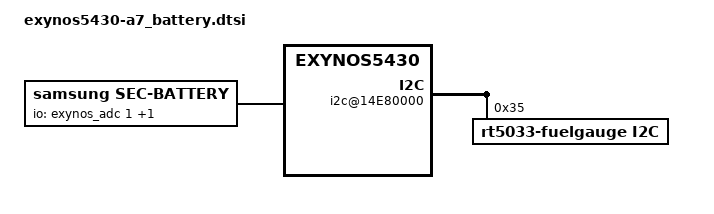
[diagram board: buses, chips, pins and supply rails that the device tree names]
/*
 * SAMSUNG UNIVERSAL5430 board device tree source
 *
 * Copyright (c) 2013 Samsung Electronics Co., Ltd.
 *		http://www.samsung.com
 *
 * This program is free software; you can redistribute it and/or modify
 * it under the terms of the GNU General Public License version 2 as
 * published by the Free Software Foundation.
*/

/ {
	i2c@14E80000 {
		compatible = "samsung,s3c2440-i2c";
		reg = <0x14E80000 0x1000>;
		interrupts = <0 443 0>;
		#address-cells = <1>;
		#size-cells = <0>;
		pinctrl-names = "default";
		pinctrl-0 = <&i2c4_bus>;
		clocks = <&clock 897>, <&clock 2447>;
		clock-names = "rate_i2c","gate_i2c";
		status = "okay";
		
		rt5033-fuelgauge@35 {
			compatible = "rt5033-fuelgauge,i2c";
			reg = <0x35>;
			interrupt-parent = <&gpa1>;
			pinctrl-names = "default";
			pinctrl-0 = <&fuel_irq>;
			
			fuelgauge,irqf = "IRQF_TRIGGER_FALLING + IRQF_ONESHOT + IRQF_NO_SUSPEND";
			fuelgauge,fuel_int = <&gpa1 5 0>;
			fuelgauge,capacity_max = <1000>;
			fuelgauge,capacity_max_margin = <50>;
			fuelgauge,capacity_min = <0>;
			fuelgauge,capacity_calculation_type = <0x17>;
			fuelgauge,fuel_alert_soc = <1>;
		};
	};

	battery {
		status = "okay";
		compatible = "samsung,sec-battery";
		battery,vendor = "SDI SDI";
		battery,charger_name = "rt5033-charger";
		battery,fuelgauge_name = "rt5033-fuelgauge";
		battery,technology = <2>; /* POWER_SUPPLY_TECHNOLOGY_LION */

		battery,chip_vendor = "LSI";
		battery,temp_adc_type = <1>; /* SEC_BATTERY_ADC_TYPE_AP */

		battery,polling_time = <10 30 30 30 3600>;

		battery,chg_temp_check = <0>;
		
		battery,inbat_voltage = <1>;




		battery,inbat_voltage_table_adc = <2902 2874 2850 2864 2796 2793 2785 2789 2781 2763
							2757 2745 2734 2724 2710 2700 2689 2679 2669 2654
							2638 2621 2612 2611 2591 2586 2574 2572 2548 2538
							2529 2510 2498 2484 2481 2468 2457 2448 2436 2421
							2404 2397 2382 2373 2357 2346 2337 2322 2308 2296
							2285 2271 2259 2250 2233>;

		battery,inbat_voltage_table_data = <4345 4325 4301 4282 4217 4215 4208 4206 4193 4173
							4153 4136 4117 4098 4078 4058 4041 4018 4001 3982
							3963 3945 3927 3908 3887 3868 3850 3832 3813 3792
							3775 3756 3737 3718 3698 3680 3661 3642 3623 3603
							3585 3563 3546 3528 3507 3488 3467 3443 3430 3400
							3383 3366 3346 3325 3301>;


		battery,temp_table_adc = <265 325 401 485 570 658 762 890 1036 1203
					1385 1591 1810 2035 2274 2507 2725 2938 3055 3120
					3190 3230 3300 3355 3480 3610 3700>;
		battery,temp_table_data = <900 850 800 750 700 650 600 550 500 450
					400 350 300 250 200 150 100 50 20 0
					(-20) (-30) (-50) (-70) (-100) (-150) (-200)>;
		battery,adc_check_count = <5>;

		battery,input_current_limit = <1500 500 500 1500 500 1000 1000 500 500 1000 1000 1500 1500 500 1000 500 700 1000 500 1000 1500 500 500>;
		battery,fast_charging_current = <2000 0 500 2000 500 1000 1000 500 0 1200 2000 2000 2000 (-1) 1300 500 800 1300 500 1000 2000 0 0>;
		battery,full_check_current_1st = <200 0 200 200 200 200 200 200 0 200 200 200 200 0 200 200 200 200 200 200 200 0 0>;
		battery,full_check_current_2nd = <2400 0 2400 2400 2400 2400 2400 2400 0 2400 2400 2400 2400 0 2400 2400 2400 2400 2400 2400 2400 0 0>;


	
	
		battery,cable_check_type = <4>; /* SEC_BATTERY_CABLE_CHECK_PSY */
		battery,cable_source_type = <3>; /* SEC_BATTERY_CABLE_SOURCE_EXTERNAL */
		battery,event_check;
		battery,event_waiting_time = <600>;
		battery,polling_type = <1>; /* SEC_BATTERY_MONITOR_ALARM */
		battery,monitor_initial_count = <3>;

		battery,battery_check_type = <0>; /* SEC_BATTERY_CHECK_NONE */
		battery,check_count = <0>;
		battery,check_adc_max = <1440>;
		battery,check_adc_min = <0>;

		battery,ovp_uvlo_check_type = <3>; /* SEC_BATTERY_OVP_UVLO_CHGPOLLING */

		battery,thermal_source = <2>; /* SEC_BATTERY_THERMAL_SOURCE_ADC */

		
		battery,temp_highlimit_threshold_event = <800>;
		battery,temp_highlimit_recovery_event = <750>;
		battery,temp_highlimit_threshold_normal = <800>;
		battery,temp_highlimit_recovery_normal = <750>;
		battery,temp_highlimit_threshold_lpm = <800>;
		battery,temp_highlimit_recovery_lpm = <750>;
		
		battery,temp_check_type = <2>; /* SEC_BATTERY_TEMP_CHECK_TEMP */
		battery,temp_check_count = <1>;
		battery,temp_high_threshold_event = <580>;
		battery,temp_high_recovery_event = <530>;
		battery,temp_low_threshold_event = <(-50)>;
		battery,temp_low_recovery_event = <(-10)>;
		battery,temp_high_threshold_normal = <580>;
		battery,temp_high_recovery_normal = <530>;
		battery,temp_low_threshold_normal = <(-50)>;
		battery,temp_low_recovery_normal = <(-10)>;
		battery,temp_high_threshold_lpm = <580>;
		battery,temp_high_recovery_lpm = <530>;
		battery,temp_low_threshold_lpm = <(-50)>;
		battery,temp_low_recovery_lpm = <(-10)>;
		battery,full_check_type = <7>; /* SEC_BATTERY_FULLCHARGED_CHGPSY */
		battery,full_check_type_2nd = <7>; /* SEC_BATTERY_FULLCHARGED_CHGPSY */
		battery,full_check_count = <1>;
		battery,chg_gpio_full_check = <0>;
		battery,chg_polarity_full_check = <1>;

		/* SEC_BATTERY_FULL_CONDITION_SOC |
		   SEC_BATTERY_FULL_CONDITION_NOTIMEFULL |
		   SEC_BATTERY_FULL_CONDITION_VCELL */
		battery,full_condition_type = <13>;
		battery,full_condition_soc = <93>;
		battery,full_condition_vcell = <4250>;

		battery,recharge_check_count = <5>;
		battery,recharge_condition_type = <4>; /* SEC_BATTERY_RECHARGE_CONDITION_VCELL */
		battery,recharge_condition_soc = <98>;
		battery,recharge_condition_vcell = <4300>;

		battery,charging_total_time = <21600>;
		battery,recharging_total_time = <5400>;
		battery,charging_reset_time = <0>;
		battery,chg_float_voltage = <4350>;

		io-channels = <&exynos_adc 1>, <&exynos_adc 3>;
		io-channel-names = "adc-temp", "inbatt-adc-temp";
		#io-channel-cells = <2>;
		io-channel-ranges;

		charger{
			status = "disable";
			/* Charger */
			battery,charger_name = "rt5033-charger";
			battery,chg_gpio_en = <0>;
			battery,chg_polarity_en = <0>;
			battery,chg_gpio_status = <0>;
			battery,chg_polarity_status = <0>;
			battery,chg_float_voltage = <4350>;
			battery,ovp_uvlo_check_type = <3>; /* SEC_BATTERY_OVP_UVLO_CHGPOLLING */
			battery,full_check_type = <2>; /* SEC_BATTERY_FULLCHARGED_FG_CURRENT */

			battery,input_current_limit = <1500 500 500 1500 500 1000 1000 500 500 1000 1000 1500 1500 500 1000 500 700 1000 500 1000 1500 500 500>;
			battery,fast_charging_current = <1500 0 500 1500 500 1000 1000 500 0 1200 1500 1500 1500 (-1) 1300 500 800 1300 500 1000 1500 0 0>;
			battery,full_check_current_1st = <200 0 200 200 200 200 200 200 0 200 200 200 200 0 200 200 200 200 200 200 200 0 0>;
			battery,full_check_current_2nd = <150 0 150 150 150 150 150 150 0 150 150 150 150 0 150 150 150 150 150 150 150 0 0>;

			
		};
	};
	battery_params {
		battery,id = <0>; /* -1 means auto, detected by F/G */ 
		battery0,battery_type = <4350>; /* 4200 4350 4400 */ 
		battery0,vg_comp_interpolation_order = <1 1>; /* necessary */
		battery0,vg_comp_idle_size = <10 3>; /* necessary */
		battery0,vg_comp_idle_data = <3200  (-1)  45  15  5   245
		                              3688  (-1)  45  15  5   245
		                              3735  (-1)  45  15  5   245
		                              3780  (-1)  45  15  5   245
		                              3810  (-1)  45  15  5   245
		                              3853  (-1)  45  15  5   245
		                              3926  (-1)  45  15  5   245
		                              4021  (-1)  45  15  5   245
		                              4115  (-1)  45  15  5   245
		                              4218  (-1)  45  15  5   245
		                              3200  0     15  50  45  135
		                              3688  0     15  50  45  135
		                              3735  0     15  50  60  135
		                              3780  0     15  45  60  135
		                              3810  0     15  45  60  135
		                              3853  0     15  60  60  135
		                              3926  0     15  60  60  135
		                              4021  0     15  60  60  135
		                              4115  0     15  60  30  135
		                              4218  0     180 255 30  135
		                              3200  400   55  85  45  135
		                              3688  400   55  60  45  135
		                              3735  400   55  35  60  135
		                              3780  400   55  35  60  135
		                              3810  400   55  35  60  135
		                              3853  400   55  60  60  135
		                              3926  400   55  62  60  135
		                              4021  400   55  62  60  135
		                              4115  400   55  72  30  135
		                              4218  400   180 230 30  135>;
		battery0,vg_comp_normal_size = <10 3>; /* necessary */
		battery0,vg_comp_normal_data = <3200  (-1)  45  15  5   245
		                                3688  (-1)  45  15  5   245
		                                3735  (-1)  45  15  5   245
		                                3780  (-1)  45  15  5   245
		                                3810  (-1)  45  15  5   245
		                                3853  (-1)  45  15  5   245
		                                3926  (-1)  45  15  5   245
		                                4021  (-1)  45  15  5   245
		                                4115  (-1)  45  15  5   245
		                                4218  (-1)  45  15  5   245
		                                3200  0     15  50  45  135
		                                3688  0     15  50  45  135
		                                3735  0     15  50  60  135
		                                3780  0     15  45  60  135
		                                3810  0     15  45  60  135
		                                3853  0     15  60  60  135
		                                3926  0     15  60  60  135
		                                4021  0     15  60  60  135
		                                4115  0     15  60  30  135
		                                4218  0     180 255 30  135
		                                3200  400   55  85  45  135
		                                3688  400   55  60  45  135
		                                3735  400   55  35  60  135
		                                3780  400   55  35  60  135
		                                3810  400   55  35  60  135
		                                3853  400   55  60  60  135
		                                3926  400   55  62  60  135
		                                4021  400   55  62  60  135
		                                4115  400   55  72  30  135
		                                4218  400   180 230 30  135>;
		battery0,special_case = <0>;
		battery0,offset_interpolation_order = <2 2>; /* necessary */
		battery0,offset_charging_size = <2 1>; /* m x n, m: volt or soc, n : temp */
		battery0,offset_charging_data = <0 250 0
						1030 250 0>;
		battery0,offset_discharging_size = <2 1>;
		battery0,offset_discharging_data = <0 250 0
						1030 250 0>;
		battery0,offset_special_size = <0 0>;
		battery0,offset_special_data = <0 0 0>;	
		battery0,offset_low_power_size = <8 1>;
		/* 4294967284 = -12 */
		battery0,offset_low_power_data = <0    250 (-12)
						15   250 (-5)
						19   250 (-9)
						20   250 (-10)
						100  250 0
						500  250 0
						970  250 (20)
						1000 250 0>;
		battery0,crate_idle_thres = <255>;
	};
};

